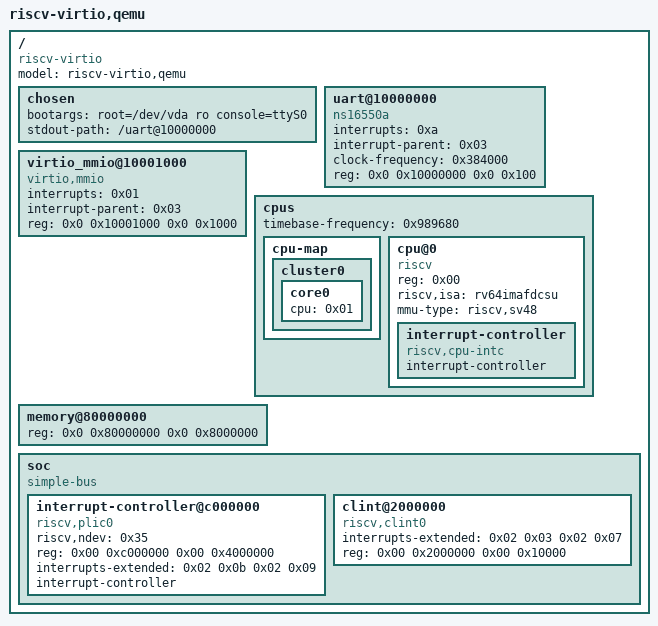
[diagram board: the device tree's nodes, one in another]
/dts-v1/;

/ {
    #address-cells = <0x02>;
    #size-cells = <0x02>;
    compatible = "riscv-virtio";
    model = "riscv-virtio,qemu";

    chosen {
        bootargs = "root=/dev/vda ro console=ttyS0";
        stdout-path = "/uart@10000000";
    };

    uart@10000000 {
        interrupts = <0xa>;
        interrupt-parent = <0x03>;
        clock-frequency = <0x384000>;
        reg = <0x0 0x10000000 0x0 0x100>;
        compatible = "ns16550a";
    };

    virtio_mmio@10001000 {
        interrupts = <0x01>;
        interrupt-parent = <0x03>;
        reg = <0x0 0x10001000 0x0 0x1000>;
        compatible = "virtio,mmio";
    };

    cpus {
        #address-cells = <0x01>;
        #size-cells = <0x00>;
        timebase-frequency = <0x989680>;

        cpu-map {
            cluster0 {
                core0 {
                    cpu = <0x01>;
                };
            };
        };

        cpu@0 {
            phandle = <0x01>;
            device_type = "cpu";
            reg = <0x00>;
            status = "okay";
            compatible = "riscv";
            riscv,isa = "rv64imafdcsu";
            mmu-type = "riscv,sv48";

            interrupt-controller {
                #interrupt-cells = <0x01>;
                interrupt-controller;
                compatible = "riscv,cpu-intc";
                phandle = <0x02>;
            };
        };
    };

	memory@80000000 {
		device_type = "memory";
		reg = <0x0 0x80000000 0x0 0x8000000>;
	};

    soc {
        #address-cells = <0x02>;
        #size-cells = <0x02>;
        compatible = "simple-bus";
        ranges;

        interrupt-controller@c000000 {
            phandle = <0x03>;
            riscv,ndev = <0x35>;
            reg = <0x00 0xc000000 0x00 0x4000000>;
            interrupts-extended = <0x02 0x0b 0x02 0x09>;
            interrupt-controller;
            compatible = "riscv,plic0";
            #interrupt-cells = <0x01>;
            #address-cells = <0x00>;
        };

        clint@2000000 {
            interrupts-extended = <0x02 0x03 0x02 0x07>;
            reg = <0x00 0x2000000 0x00 0x10000>;
            compatible = "riscv,clint0";
        };
    };
};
